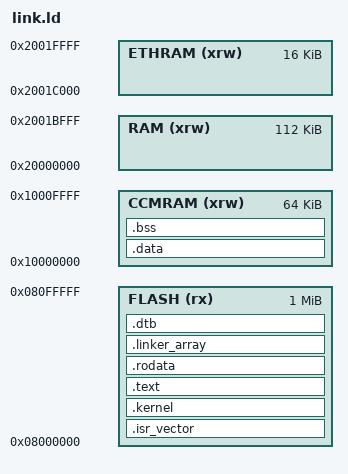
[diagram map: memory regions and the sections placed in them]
/*
 * Copyright (C) 2013 F4OS Authors
 *
 * Permission is hereby granted, free of charge, to any person obtaining a copy of
 * this software and associated documentation files (the "Software"), to deal in
 * the Software without restriction, including without limitation the rights to
 * use, copy, modify, merge, publish, distribute, sublicense, and/or sell copies
 * of the Software, and to permit persons to whom the Software is furnished to do
 * so, subject to the following conditions:
 *
 * The above copyright notice and this permission notice shall be included in all
 * copies or substantial portions of the Software.
 *
 * THE SOFTWARE IS PROVIDED "AS IS", WITHOUT WARRANTY OF ANY KIND, EXPRESS OR
 * IMPLIED, INCLUDING BUT NOT LIMITED TO THE WARRANTIES OF MERCHANTABILITY,
 * FITNESS FOR A PARTICULAR PURPOSE AND NONINFRINGEMENT. IN NO EVENT SHALL THE
 * AUTHORS OR COPYRIGHT HOLDERS BE LIABLE FOR ANY CLAIM, DAMAGES OR OTHER
 * LIABILITY, WHETHER IN AN ACTION OF CONTRACT, TORT OR OTHERWISE, ARISING FROM,
 * OUT OF OR IN CONNECTION WITH THE SOFTWARE OR THE USE OR OTHER DEALINGS IN THE
 * SOFTWARE.
 */

/* Specify the memory areas */
MEMORY
{
  FLASH (rx)      : ORIGIN = 0x08000000, LENGTH = 1024K
  RAM (xrw)       : ORIGIN = 0x20000000, LENGTH = 112K
  ETHRAM (xrw)    : ORIGIN = 0x2001C000, LENGTH = 16K
  CCMRAM (xrw)    : ORIGIN = 0x10000000, LENGTH = 64K
}

/* Highest address of the kernel stack */
_estack = 0x10008000;    /* middle of 64K CCM RAM */

/* Heap */
_suserheap = CONFIG_SUSERHEAP;
_euserheap = CONFIG_EUSERHEAP;
_skernelheap = CONFIG_SKERNELHEAP;
_ekernelheap = CONFIG_EKERNELHEAP;

SECTIONS {
    /* Vectors first - Always permitted by MPU */
    .isr_vector :
    {
        . = ALIGN(4);
        KEEP(*(.isr_vector))
        . = ALIGN(4);
    } > FLASH

    .kernel :
    {
        . = ALIGN(8);
        _skernel = .;
        *(.kernel*)
        . = ALIGN(8);
        _ekernel = .;
    } > FLASH

    .text :
    {
        . = ALIGN(8);
        _stext = .;
        *(.text*)
        . = ALIGN(8);

        _etext = .;
    } > FLASH

    .rodata :
    {
        . = ALIGN(8);
        *(.rodata*)
        . = ALIGN(8);
    } > FLASH

    .linker_array :
    {
        KEEP(*(SORT_BY_NAME(.linker_array.*)))
    } > FLASH

    .dtb :
    {
        . = ALIGN(8);
        _dtb_start = .;
        *(.dtb*)
        _dtb_end = .;
        . = ALIGN(8);
    } > FLASH

    _sidata = .;
    .data : AT ( _sidata )
    {
        . = ALIGN(4);
        _sdata = .;        /* create a global symbol at data start */
        *(.data*)           /* .data sections */

        . = ALIGN(4);
        _edata = .;        /* define a global symbol at data end */
    } > CCMRAM

    /* Uninitialized data section */
    _sibss = .;
    .bss : AT ( _sibss )
    {
        . = ALIGN(4);
        _sbss = .;         /* define a global symbol at bss start */
        *(.bss*)
        *(COMMON)

        . = ALIGN(4);
        _ebss = .;         /* define a global symbol at bss end */
    } > CCMRAM
}

PROVIDE(end = .);
_end            = .;
